# max32630 register map
Vendor: Maxim Integrated; Series: max3263x; File version: 1.2
CPU: CM4 r0p1, little endian, no MPU, FPU, 3 interrupt priority bits
Registers are 32-bit, read-write, reset 0x0 unless marked. A register's access mark holds for its fields unless they carry their own. Offsets are from the block's base; [hi:lo] are bit positions; {n}, {i} and the like mark numbered series.

## USB — USB Device Controller
Base 0x40100000
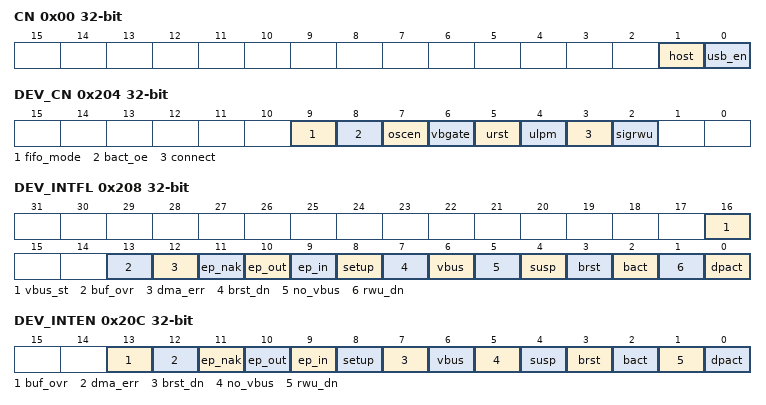
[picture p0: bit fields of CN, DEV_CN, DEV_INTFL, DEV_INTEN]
0x00 CN — USB Control Register
  [1] host — USB Host Mode Select
  [0] usb_en — USB Device Interface Enable
0x200 DEV_ADDR — USB Device Address Register
  [6:0] dev_addr ro — USB Device Address
0x204 DEV_CN — USB Device Control Register
  [9] fifo_mode
  [8] bact_oe
  [7] oscen
  [6] vbgate — VBUS Gate
  [5] urst — USB Device Controller Reset
  [4] ulpm — USB Low Power Mode
  [3] connect — Connect to USB
  [2] sigrwu — USB Signal Remote Wakeup
0x208 DEV_INTFL — USB Device Interrupt
  [16] vbus_st ro — VBUS Status
  [13] buf_ovr write-1-clears — Buffer Overflow Interrupt Flag
  [12] dma_err write-1-clears — DMA Error Interrupt Flag
  [11] ep_nak write-1-clears — Endpoint NAK Interrupt Flag
  [10] ep_out write-1-clears — Endpoint OUT Interrupt Flag
  [9] ep_in write-1-clears — Endpoint IN Interrupt Flag
  [8] setup write-1-clears — Setup Packet Interrupt Flag
  [7] brst_dn write-1-clears — USB Bus Reset Completed Interrupt Flag
  [6] vbus write-1-clears — VBUS Detect Interrupt Flag
  [5] no_vbus write-1-clears — No VBUS Interrupt Flag
  [4] susp write-1-clears — USB Suspend Interrupt Flag
  [3] brst write-1-clears — USB Bus Reset In Progress Interrupt Flag
  [2] bact write-1-clears — USB Bus Activity Interrupt Flag
  [1] rwu_dn write-1-clears — Remote Wakeup Done Interrupt Flag
  [0] dpact write-1-clears — DPLUS Activity Interrupt Flag
0x20C DEV_INTEN — USB Device Interrupt Enable
  [13] buf_ovr — Buffer Overflow Interrupt Enable
  [12] dma_err — DMA Error Interrupt Enable
  [11] ep_nak — Endpoint NAK Interrupt Enable
  [10] ep_out — Endpoint OUT Interrupt Enable
  [9] ep_in — Endpoint IN Interrupt Enable
  [8] setup — Setup Packet Interrupt Enable
  [7] brst_dn — USB Bus Reset Completed Interrupt Enable
  [6] vbus — VBUS Detect Interrupt Enable
  [5] no_vbus — No VBUS Interrupt Enable
  [4] susp — USB Suspend Interrupt Enable
  [3] brst — USB Bus Reset In Progress Interrupt Enable
  [2] bact — USB Bus Activity Interrupt Enable
  [1] rwu_dn — Remote Wakeup Done Interrupt Enable
  [0] dpact — DPLUS Activity Interrupt Enable
0x220 EP_BASE — USB Endpoint Descriptor Table Base Address
  [31:9] ep_base
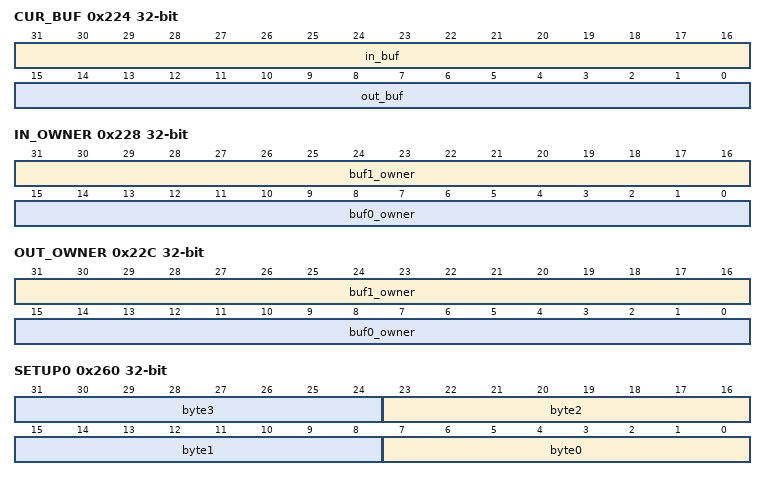
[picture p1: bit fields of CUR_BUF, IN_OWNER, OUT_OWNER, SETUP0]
0x224 CUR_BUF — USB Current Endpoint Buffer Register
  [31:16] in_buf ro — IN Transfer Current Buffers
  [15:0] out_buf ro — OUT Transfer Current Buffers
0x228 IN_OWNER — USB IN Endpoint Buffer Owner Register
  [31:16] buf1_owner — Owner for IN Buffer 1 for Endpoints
  [15:0] buf0_owner — Owner for IN Buffer 0 for Endpoints
0x22C OUT_OWNER — USB OUT Endpoint Buffer Owner Register
  [31:16] buf1_owner — Owner for OUT Buffer 1 for Endpoints
  [15:0] buf0_owner — Owner for OUT Buffer 0 for Endpoints
0x230 IN_INT — USB IN Endpoint Buffer Available Interrupt
  [7:0] inbav write-1-clears — Endpoint Buffer Available Interrupt Flags
0x234 OUT_INT — USB OUT Endpoint Data Available Interrupt
  [7:0] outdav write-1-clears — Endpoint Data Available Interrupt Flags
0x238 NAK_INT — USB IN Endpoint NAK Interrupt
  [7:0] nak write-1-clears — Endpoint NAK Interrupt Flags
0x23C DMA_ERR_INT — USB DMA Error Interrupt
  [7:0] dma_err write-1-clears — Endpoint DMA Error Interrupt Flags
0x240 BUF_OVR_INT — USB Buffer Overflow Interrupt
  [7:0] buf_ovr write-1-clears — Endpoint Buffer Overflow Interrupt Flags
0x260 SETUP0 — USB SETUP Packet Bytes 0 to 3
  [8n+7:8n] byte{n} ro (n=0..3) — SETUP Packet Byte {n}
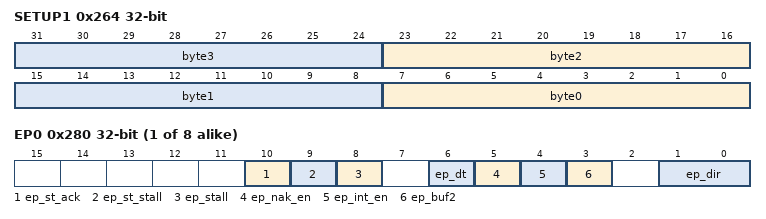
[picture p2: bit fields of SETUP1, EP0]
0x264 SETUP1 — USB SETUP Packet Bytes 4 to 7
  [8n+7:8n] byte{n} ro (n=0..3) — SETUP Packet Byte {n+4}
{0x280+4i} EP{i} (i=0..7) — USB Endpoint {i} Control Register
  [10] ep_st_ack — Endpoint Acknowledge Status Stage of Control Transfer
  [9] ep_st_stall — Endpoint Stall Status Stage of Control Transfer
  [8] ep_stall — Endpoint Stall
  [6] ep_dt — Endpoint Data Toggle Clear
  [5] ep_nak_en — Endpoint NAK Interrupt Enable
  [4] ep_int_en — Endpoint Transfer Complete Interrupt Enable
  [3] ep_buf2 — Endpoint Double Buffered Enable
  [1:0] ep_dir — Endpoint Direction
